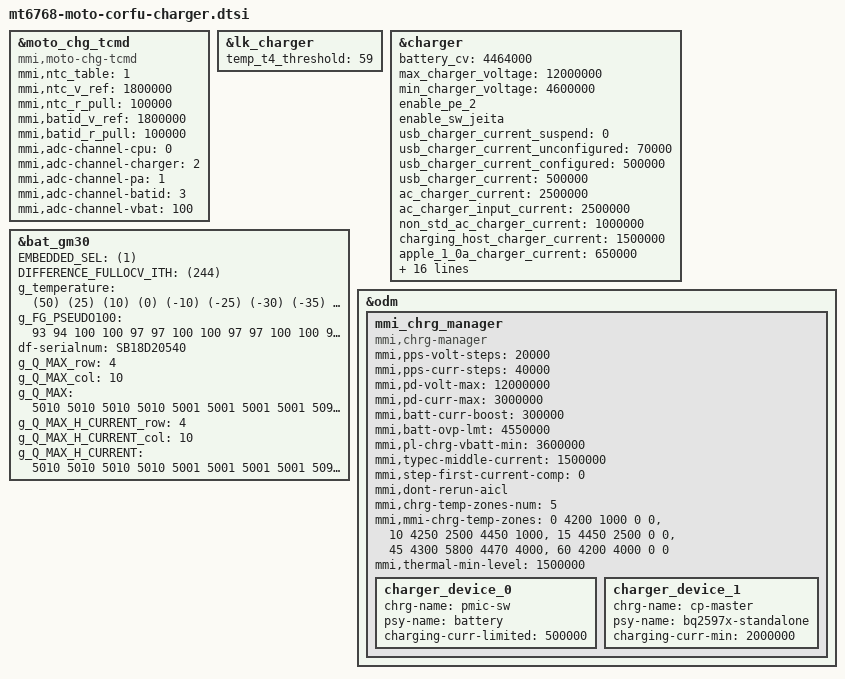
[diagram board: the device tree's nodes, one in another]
/*
 * Copyright (c) 2019 MediaTek Inc.
 *
 * This program is free software; you can redistribute it and/or modify
 * it under the terms of the GNU General Public License version 2 as
 * published by the Free Software Foundation.
 *
 * This program is distributed in the hope that it will be useful,
 * but WITHOUT ANY WARRANTY; without even the implied warranty of
 * MERCHANTABILITY or FITNESS FOR A PARTICULAR PURPOSE.  See the
 * GNU General Public License for more details.
 */

&moto_chg_tcmd {
                compatible = "mmi,moto-chg-tcmd";
                status = "okay";

                mmi,ntc_table = <1>;
                mmi,ntc_v_ref = <1800000>;
                mmi,ntc_r_pull = <100000>;

                mmi,batid_v_ref = <1800000>;
                mmi,batid_r_pull = <100000>;

                mmi,adc-channel-cpu = <0>;
                mmi,adc-channel-charger = <2>;
                mmi,adc-channel-pa = <1>;
                mmi,adc-channel-batid = <3>;
                mmi,adc-channel-vbat = <100>;
};

&lk_charger {
        temp_t4_threshold = <59>;
};

&charger {
        /* common */
        battery_cv = <4464000>;
        max_charger_voltage = <12000000>;
        min_charger_voltage = <4600000>;

        enable_pe_2;
        enable_sw_jeita;

        /* charging current */
        usb_charger_current_suspend = <0>;
        usb_charger_current_unconfigured = <70000>;
        usb_charger_current_configured = <500000>;
        usb_charger_current = <500000>;
        ac_charger_current = <2500000>;
        ac_charger_input_current = <2500000>;
        non_std_ac_charger_current = <1000000>;
        charging_host_charger_current = <1500000>;
        apple_1_0a_charger_current = <650000>;
        apple_2_1a_charger_current = <800000>;
        ta_ac_charger_current = <2000000>;
        typec_limit_aicr = <2000000>;

        //mmi config
        mmi,iterm-ma = <243>;
        mmi,mmi-temp-zones =
                       <0 4200 1000  0>,
                       <10 4250 2500 1000>,
//                       <10 4450 1000 0>,
                       <15 4450 2500 0>,
                       <25 0 4000 4000>,
//                       <25 4480 4000 0>,
                       <35 0 4000 4000>,
//                       <35 4480 4000 0>,
                       <45 0 4000 4000>,
//                       <45 4480 4000 0>,
                       <60 4200 4000 0>;

	mmi,mmi-ffc-zones =
                        <4200 243>,
                        <4450 243>,
                        <4450 243>,
                        <4480 550>,
                        <4480 588>,
                        <4480 631>,
                        <4200 243>;

        mmi,enable-charging-limit;
        mmi,upper-limit-capacity = <65>;
        mmi,lower-limit-capacity = <60>;
        mmi,vfloat-comp-uv = <20000>;
	enable_cp;
};

&bat_gm30 {
        //io-channels = <&auxadc 5>;
        //io-channel-names = "batteryID-channel";
        EMBEDDED_SEL = <(1)>;   /* embedded battery.*/
        DIFFERENCE_FULLOCV_ITH = <(244)>;       /*Charging termination current.*/

        /* battery prop */
        g_temperature = <(50) (25) (10) (0) (-10) (-25) (-30) (-35) (-40) (-45)>;

        g_FG_PSEUDO100 = <93 94 100 100
                97 97 100 100
                97 97 100 100
                97 97 100 100
                93 94 100 100
                100 100 100 100
                100 100 100 100
                100 100 100 100
                100 100 100 100
                100 100 100 100>;

        df-serialnum = "SB18D20540";//SB18D20541
	g_Q_MAX_row = <4>;
	g_Q_MAX_col = <10>;
	g_Q_MAX = <
		/*bat1,   bat2,   bat3,    bat4*/
		5010 5010 5010 5010/*T0*/
		5001 5001 5001 5001/*T1*/
		5098 5098 5098 5098/*T2*/
		5098 5098 5098 5098/*T3*/
		4851 4851 4851 4851/*T4*/
		3488 3488 3488 3488/*T5*/
		3488 3488 3488 3488/*T6*/
		3488 3488 3488 3488/*T7*/
		3488 3488 3488 3488/*T8*/
		3488 3488 3488 3488/*T9*/
	>;
	g_Q_MAX_H_CURRENT_row = <4>;
	g_Q_MAX_H_CURRENT_col = <10>;
	g_Q_MAX_H_CURRENT = <
		/*bat1,   bat2,   bat3,    bat4*/
		5010 5010 5010 5010/*T0*/
		5001 5001 5001 5001/*T1*/
		5098 5098 5098 5098/*T2*/
		5098 5098 5098 5098/*T3*/
		4851 4851 4851 4851/*T4*/
		3488 3488 3488 3488/*T5*/
		3488 3488 3488 3488/*T6*/
		3488 3488 3488 3488/*T7*/
		3488 3488 3488 3488/*T8*/
		3488 3488 3488 3488/*T9*/
	>;
        #include "bat_setting/mt6768_battery_table_NC50_5000mah_ext.dtsi"
	#include "bat_setting/mt6768_battery_table_NC50_5000mah_SCUD_ext.dtsi"
};

&odm {
	mmi_chrg_manager {
		compatible = "mmi,chrg-manager";
		mmi,pps-volt-steps = <20000>;
		mmi,pps-curr-steps = <40000>;
		mmi,pd-volt-max = <12000000>;
		mmi,pd-curr-max = <3000000>;
		mmi,batt-curr-boost = <300000>;
		mmi,batt-ovp-lmt = <4550000>;
		mmi,pl-chrg-vbatt-min = <3600000>;
		mmi,typec-middle-current = <1500000>;
		mmi,step-first-current-comp = <0>;
		mmi,dont-rerun-aicl;
		mmi,chrg-temp-zones-num = <5>;
		mmi,mmi-chrg-temp-zones =
					<0 4200 1000  0 0>,
					<10 4250 2500 4450 1000>,
					<15 4450 2500 0 0>,
					<45 4300 5800 4470 4000>,
					<60 4200 4000 0 0>;
/*
            mmi,mmi-ffc-zones = <4200 243>,
                                <4250 243>,
                                <4450 243>,
                                <4480 550>,
                                <4480 588>,
                                <4480 631>,
                                <4200 243>;
*/
		mmi,thermal-min-level = <1500000>;
		charger_device_0 {
			chrg-name = "pmic-sw";
			psy-name = "battery";
			charging-curr-limited = <500000>;
		};
		charger_device_1 {
			chrg-name = "cp-master";
			psy-name = "bq2597x-standalone";
			charging-curr-min = <2000000>;
		};
	};
};
